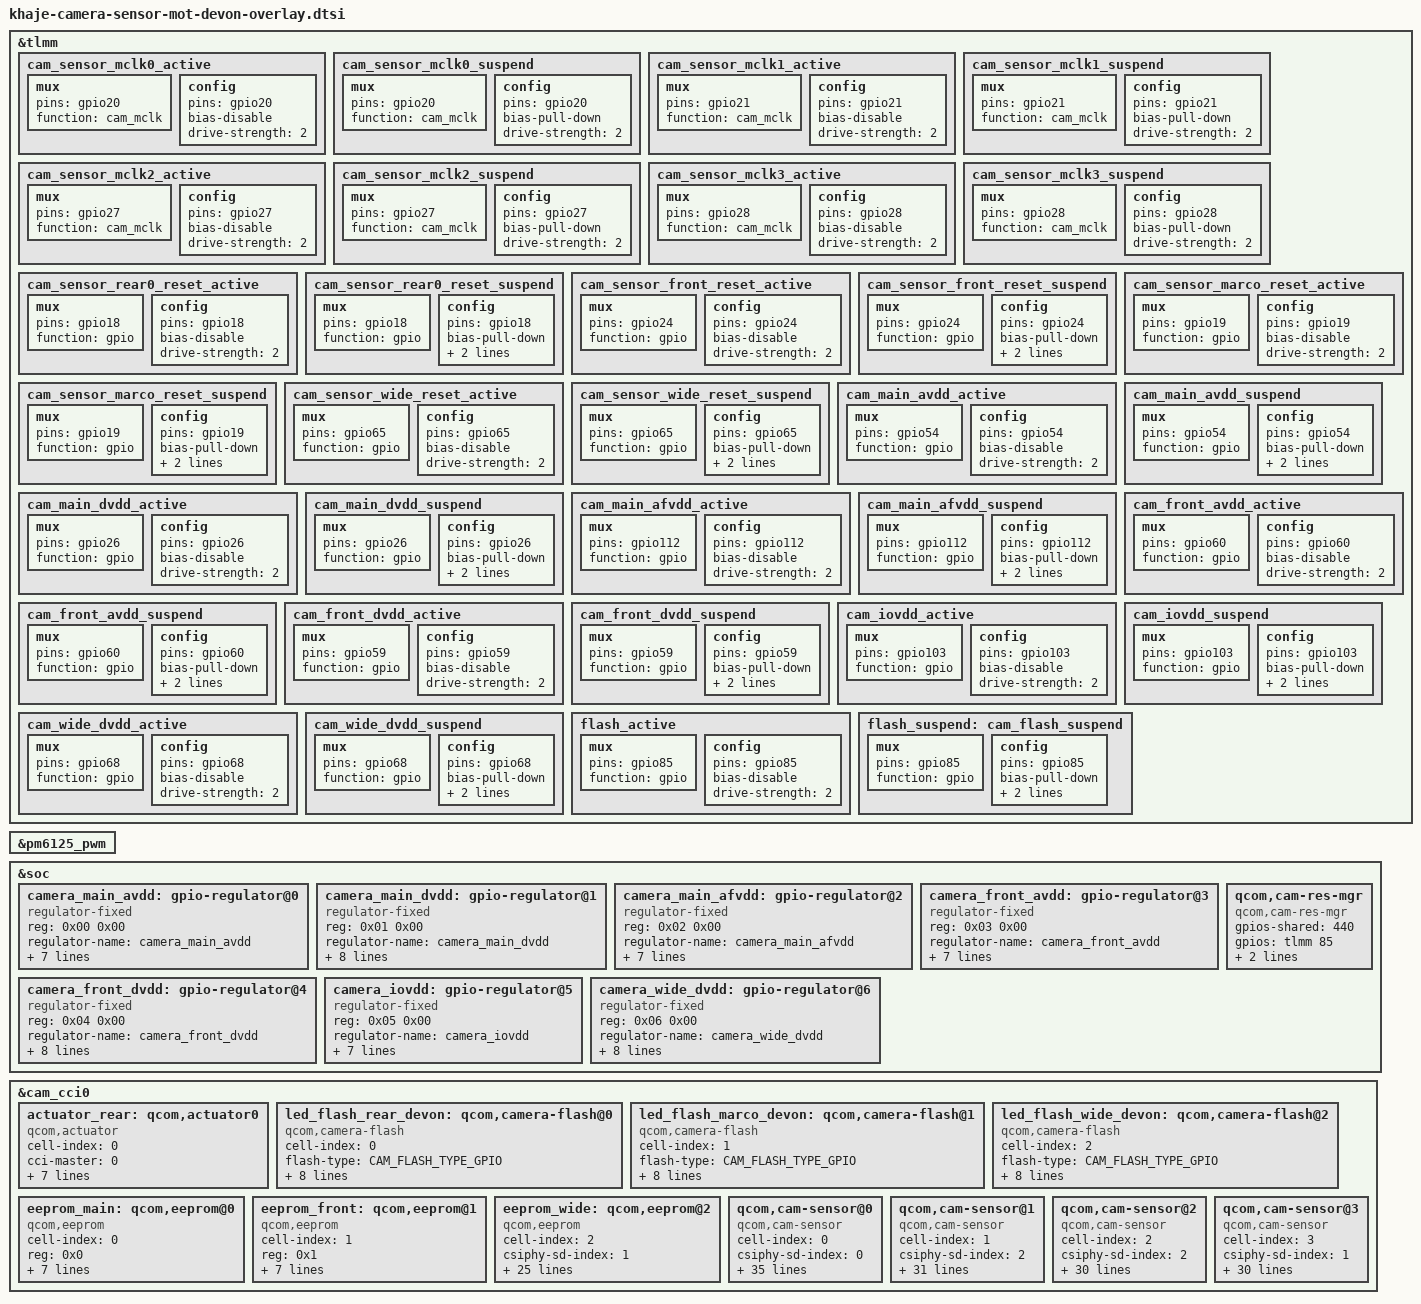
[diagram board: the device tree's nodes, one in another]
#include <dt-bindings/clock/qcom,gcc-khaje.h>
#include <dt-bindings/msm/msm-camera.h>
#include "khaje-camera-flash-pwm.dtsi"

&tlmm {
	cam_sensor_mclk0_active: cam_sensor_mclk0_active {
		/* MCLK 0*/
		mux {
			pins = "gpio20";
			function = "cam_mclk";
		};

		config {
			pins = "gpio20";
			bias-disable;
			drive-strength = <2>;
		};
	};

	cam_sensor_mclk0_suspend: cam_sensor_mclk0_suspend {
		/* MCLK 0*/
		mux {
			pins = "gpio20";
			function = "cam_mclk";
		};

		config {
			pins = "gpio20";
			bias-pull-down;
			drive-strength = <2>;
		};
	};

	cam_sensor_mclk1_active: cam_sensor_mclk1_active {
		mux {
			pins = "gpio21";
			function = "cam_mclk";
		};

		config {
			pins = "gpio21";
			bias-disable; /* No PULL */
			drive-strength = <2>; /* 2 MA */
		};
	};

	cam_sensor_mclk1_suspend: cam_sensor_mclk1_suspend {
		mux {
			pins = "gpio21";
			function = "cam_mclk";
		};

		config {
			pins = "gpio21";
			bias-pull-down;
			drive-strength = <2>; /* 2 MA */
		};
	};

	cam_sensor_mclk2_active: cam_sensor_mclk2_active {
		mux {
			pins = "gpio27";
			function = "cam_mclk";
		};

		config {
			pins = "gpio27";
			bias-disable; /* No PULL */
			drive-strength = <2>; /* 2 MA */
		};
	};

	cam_sensor_mclk2_suspend: cam_sensor_mclk2_suspend {
		mux {
			pins = "gpio27";
			function = "cam_mclk";
		};

		config {
			pins = "gpio27";
			bias-pull-down;
			drive-strength = <2>; /* 2 MA */
		};
	};

	cam_sensor_mclk3_active: cam_sensor_mclk3_active {
		mux {
			pins = "gpio28";
			function = "cam_mclk";
		};

		config {
			pins = "gpio28";
			bias-disable; /* No PULL */
			drive-strength = <2>; /* 2 MA */
		};
	};

	cam_sensor_mclk3_suspend: cam_sensor_mclk3_suspend {
		mux {
			pins = "gpio28";
			function = "cam_mclk";
		};

		config {
			pins = "gpio28";
			bias-pull-down;
			drive-strength = <2>; /* 2 MA */
		};
	};

	cam_sensor_rear0_reset_active: cam_sensor_rear0_reset_active {
		mux {
			pins = "gpio18";
			function = "gpio";
		};

		config {
			pins = "gpio18";
			bias-disable; /* No PULL */
			drive-strength = <2>;
		};
	};

	cam_sensor_rear0_reset_suspend: cam_sensor_rear0_reset_suspend {
		mux {
			pins = "gpio18";
			function = "gpio";
		};

		config {
			pins = "gpio18";
			bias-pull-down; /* PULL DOWN */
			drive-strength = <2>;
			output-low;
		};
	};

	cam_sensor_front_reset_active: cam_sensor_front_reset_active {
		mux {
			pins = "gpio24";
			function = "gpio";
		};

		config {
			pins = "gpio24";
			bias-disable; /* No PULL */
			drive-strength = <2>;
		};
	};

	cam_sensor_front_reset_suspend: cam_sensor_front_reset_suspend {
		mux {
			pins = "gpio24";
			function = "gpio";
		};

		config {
			pins = "gpio24";
			bias-pull-down; /* PULL DOWN */
			drive-strength = <2>;
			output-low;
		};
	};

	cam_sensor_marco_reset_active: cam_sensor_marco_reset_active {
		mux {
			pins = "gpio19";
			function = "gpio";
		};

		config {
			pins = "gpio19";
			bias-disable; /* No PULL */
			drive-strength = <2>;
		};
	};

	cam_sensor_marco_reset_suspend: cam_sensor_marco_reset_suspend {
		mux {
			pins = "gpio19";
			function = "gpio";
		};

		config {
			pins = "gpio19";
			bias-pull-down; /* PULL DOWN */
			drive-strength = <2>;
			output-low;
		};
	};

	cam_sensor_wide_reset_active: cam_sensor_wide_reset_active {
		mux {
			pins = "gpio65";
			function = "gpio";
		};

		config {
			pins = "gpio65";
			bias-disable; /* No PULL */
			drive-strength = <2>;
		};
	};

	cam_sensor_wide_reset_suspend: cam_sensor_wide_reset_suspend {
		mux {
			pins = "gpio65";
			function = "gpio";
		};

		config {
			pins = "gpio65";
			bias-pull-down; /* PULL DOWN */
			drive-strength = <2>;
			output-low;
		};
	};

	cam_main_avdd_active: cam_main_avdd_active {
		/* MAIN AVDD EN */
		mux {
			pins = "gpio54";
			function = "gpio";
		};

		config {
			pins = "gpio54";
			bias-disable; /* No PULL */
			drive-strength = <2>; /* 2 MA */
		};
	};

	cam_main_avdd_suspend: cam_main_avdd_suspend {
		mux {
			pins = "gpio54";
			function = "gpio";
		};

		config {
			pins = "gpio54";
			bias-pull-down; /* PULL DOWN */
			drive-strength = <2>; /* 2 MA */
			output-low;
		};
	};

	cam_main_dvdd_active: cam_main_dvdd_active {
		/* MAIN DVDD EN */
		mux {
			pins = "gpio26";
			function = "gpio";
		};

		config {
			pins = "gpio26";
			bias-disable; /* No PULL */
			drive-strength = <2>; /* 2 MA */
		};
	};

	cam_main_dvdd_suspend: cam_main_dvdd_suspend {
		mux {
			pins = "gpio26";
			function = "gpio";
		};

		config {
			pins = "gpio26";
			bias-pull-down; /* PULL DOWN */
			drive-strength = <2>; /* 2 MA */
			output-low;
		};
	};

	cam_main_afvdd_active: cam_main_afvdd_active {
		/* MAIN AFVDD EN */
		mux {
			pins = "gpio112";
			function = "gpio";
		};

		config {
			pins = "gpio112";
			bias-disable; /* No PULL */
			drive-strength = <2>; /* 2 MA */
		};
	};

	cam_main_afvdd_suspend: cam_main_afvdd_suspend {
		mux {
			pins = "gpio112";
			function = "gpio";
		};

		config {
			pins = "gpio112";
			bias-pull-down; /* PULL DOWN */
			drive-strength = <2>; /* 2 MA */
			output-low;
		};
	};

	cam_front_avdd_active: cam_front_avdd_active {
		/* FRONT AVDD EN */
		mux {
			pins = "gpio60";
			function = "gpio";
		};

		config {
			pins = "gpio60";
			bias-disable; /* No PULL */
			drive-strength = <2>; /* 2 MA */
		};
	};

	cam_front_avdd_suspend: cam_front_avdd_suspend {
		mux {
			pins = "gpio60";
			function = "gpio";
		};

		config {
			pins = "gpio60";
			bias-pull-down; /* PULL DOWN */
			drive-strength = <2>; /* 2 MA */
			output-low;
		};
	};

	cam_front_dvdd_active: cam_front_dvdd_active {
		/* FRONT DVDD EN */
		mux {
			pins = "gpio59";
			function = "gpio";
		};

		config {
			pins = "gpio59";
			bias-disable; /* No PULL */
			drive-strength = <2>; /* 2 MA */
		};
	};

	cam_front_dvdd_suspend: cam_front_dvdd_suspend {
		mux {
			pins = "gpio59";
			function = "gpio";
		};

		config {
			pins = "gpio59";
			bias-pull-down; /* PULL DOWN */
			drive-strength = <2>; /* 2 MA */
			output-low;
		};
	};

	cam_iovdd_active: cam_iovdd_active {
		/* IOVDD EN */
		mux {
			pins = "gpio103";
			function = "gpio";
		};

		config {
			pins = "gpio103";
			bias-disable; /* No PULL */
			drive-strength = <2>; /* 2 MA */
		};
	};

	cam_iovdd_suspend: cam_iovdd_suspend {
		mux {
			pins = "gpio103";
			function = "gpio";
		};

		config {
			pins = "gpio103";
			bias-pull-down; /* PULL DOWN */
			drive-strength = <2>; /* 2 MA */
			output-low;
		};
	};

	cam_wide_dvdd_active: cam_wide_dvdd_active {
		/* WIDE DVDD EN */
		mux {
			pins = "gpio68";
			function = "gpio";
		};

		config {
			pins = "gpio68";
			bias-disable; /* No PULL */
			drive-strength = <2>; /* 2 MA */
		};
	};

	cam_wide_dvdd_suspend: cam_wide_dvdd_suspend {
		mux {
			pins = "gpio68";
			function = "gpio";
		};

		config {
			pins = "gpio68";
			bias-pull-down; /* PULL DOWN */
			drive-strength = <2>; /* 2 MA */
			output-low;
		};
	};

	flash_active: flash_active {
		/* FLASH */
		mux {
			pins = "gpio85";
			function = "gpio";
		};

		config {
			pins = "gpio85";
			bias-disable; /* No PULL */
			drive-strength = <2>; /* 2 MA */
		};
	};

	flash_suspend: cam_flash_suspend {
		/* FLASH */
		mux {
			pins = "gpio85";
			function = "gpio";
		};

		config {
			pins = "gpio85";
			bias-pull-down; /* PULL DOWN */
			drive-strength = <2>; /* 2 MA */
			output-low;
		};
	};

};

&pm6125_pwm {
	status = "ok";
};

&soc {

	camera_main_avdd: gpio-regulator@0 {
		compatible = "regulator-fixed";
		reg = <0x00 0x00>;
		regulator-name = "camera_main_avdd";
		regulator-min-microvolt = <2800000>;
		regulator-max-microvolt = <2800000>;
		regulator-enable-ramp-delay = <233>;
		enable-active-high;
		gpio = <&tlmm 54 0>;
		pinctrl-names = "default";
		pinctrl-0 = <&cam_main_avdd_active>;
		pinctrl-1 = <&cam_main_avdd_suspend>;
		//vin-supply = <&VPH_PWR>;
	};

	camera_main_dvdd: gpio-regulator@1 {
		compatible = "regulator-fixed";
		reg = <0x01 0x00>;
		regulator-name = "camera_main_dvdd";
		regulator-min-microvolt = <1050000>;
		regulator-max-microvolt = <1050000>;
		regulator-enable-ramp-delay = <233>;
		enable-active-high;
		gpio = <&tlmm 26 0>;
		pinctrl-names = "default";
		pinctrl-0 = <&cam_main_dvdd_active>;
		pinctrl-1 = <&cam_main_dvdd_suspend>;
		vin-supply = <&S7A>;
	};

	camera_main_afvdd: gpio-regulator@2 {
		compatible = "regulator-fixed";
		reg = <0x02 0x00>;
		regulator-name = "camera_main_afvdd";
		regulator-min-microvolt = <2800000>;
		regulator-max-microvolt = <2800000>;
		regulator-enable-ramp-delay = <233>;
		enable-active-high;
		gpio = <&tlmm 112 0>;
		pinctrl-names = "default";
		pinctrl-0 = <&cam_main_afvdd_active>;
		pinctrl-1 = <&cam_main_afvdd_suspend>;
		//vin-supply = <&VPH_PWR>;
	};

	camera_front_avdd: gpio-regulator@3 {
		compatible = "regulator-fixed";
		reg = <0x03 0x00>;
		regulator-name = "camera_front_avdd";
		regulator-min-microvolt = <2800000>;
		regulator-max-microvolt = <2800000>;
		regulator-enable-ramp-delay = <233>;
		enable-active-high;
		gpio = <&tlmm 60 0>;
		pinctrl-names = "default";
		pinctrl-0 = <&cam_front_avdd_active>;
		pinctrl-1 = <&cam_front_avdd_suspend>;
		//vin-supply = <&VPH_PWR>;
	};

	camera_front_dvdd: gpio-regulator@4 {
		compatible = "regulator-fixed";
		reg = <0x04 0x00>;
		regulator-name = "camera_front_dvdd";
		regulator-min-microvolt = <1200000>;
		regulator-max-microvolt = <1200000>;
		regulator-enable-ramp-delay = <233>;
		enable-active-high;
		gpio = <&tlmm 59 0>;
		pinctrl-names = "default";
		pinctrl-0 = <&cam_front_dvdd_active>;
		pinctrl-1 = <&cam_front_dvdd_suspend>;
		vin-supply = <&S7A>;
	};

	camera_iovdd: gpio-regulator@5 {
		compatible = "regulator-fixed";
		reg = <0x05 0x00>;
		regulator-name = "camera_iovdd";
		regulator-min-microvolt = <1800000>;
		regulator-max-microvolt = <1800000>;
		regulator-enable-ramp-delay = <233>;
		enable-active-high;
		gpio = <&tlmm 103 0>;
		pinctrl-names = "default";
		pinctrl-0 = <&cam_iovdd_active>;
		pinctrl-1 = <&cam_iovdd_suspend>;
		//vin-supply = <&VPH_PWR>;
	};

	camera_wide_dvdd: gpio-regulator@6 {
		compatible = "regulator-fixed";
		reg = <0x06 0x00>;
		regulator-name = "camera_wide_dvdd";
		regulator-min-microvolt = <1200000>;
		regulator-max-microvolt = <1200000>;
		regulator-enable-ramp-delay = <233>;
		enable-active-high;
		gpio = <&tlmm 68 0>;
		pinctrl-names = "default";
		pinctrl-0 = <&cam_wide_dvdd_active>;
		pinctrl-1 = <&cam_wide_dvdd_suspend>;
		vin-supply = <&S7A>;
	};

	qcom,cam-res-mgr {
		compatible = "qcom,cam-res-mgr";
		status = "ok";
		gpios-shared = <440>;
		gpios = <&tlmm 85 0>;
		pinctrl-names = "flash_active", "flash_suspend";
		pinctrl-0 = <&flash_active>;
		pinctrl-1 = <&flash_suspend>;
	};
};

&cam_cci0 {
	actuator_rear: qcom,actuator0 {
		cell-index = <0>;
		compatible = "qcom,actuator";
		cci-master = <0>;
		cam_vaf-supply = <&camera_main_afvdd>;
		regulator-names = "cam_vaf";
		rgltr-cntrl-support;
		rgltr-min-voltage = <2800000>;
		rgltr-max-voltage = <2800000>;
		rgltr-load-current = <2800000>;
		status = "ok";
		multi-user-support;
	};

	led_flash_rear_devon: qcom,camera-flash@0 {
		cell-index = <0>;
		compatible = "qcom,camera-flash";
		flash-type = <CAM_FLASH_TYPE_GPIO>;
		gpio-no-mux = <0>;
		pinctrl-names = "cam_default", "cam_suspend";
		pinctrl-0 = <&flash_active>;
		pinctrl-1 = <&flash_suspend>;
		gpios = <&tlmm 85 0>;
		gpio-custom1 = <0>;
		gpio-req-tbl-num = <0>;
		gpio-req-tbl-flags = <0>;
		gpio-req-tbl-label = "CUSTOM_GPIO1";
		status = "ok";
	};

	led_flash_marco_devon: qcom,camera-flash@1 {
		cell-index = <1>;
		compatible = "qcom,camera-flash";
		flash-type = <CAM_FLASH_TYPE_GPIO>;
		gpio-no-mux = <0>;
		pinctrl-names = "cam_default", "cam_suspend";
		pinctrl-0 = <&flash_active>;
		pinctrl-1 = <&flash_suspend>;
		gpios = <&tlmm 85 0>;
		gpio-custom1 = <0>;
		gpio-req-tbl-num = <0>;
		gpio-req-tbl-flags = <0>;
		gpio-req-tbl-label = "CUSTOM_GPIO1";
		status = "ok";
	};

	led_flash_wide_devon: qcom,camera-flash@2 {
		cell-index = <2>;
		compatible = "qcom,camera-flash";
		flash-type = <CAM_FLASH_TYPE_GPIO>;
		gpio-no-mux = <0>;
		pinctrl-names = "cam_default", "cam_suspend";
		pinctrl-0 = <&flash_active>;
		pinctrl-1 = <&flash_suspend>;
		gpios = <&tlmm 85 0>;
		gpio-custom1 = <0>;
		gpio-req-tbl-num = <0>;
		gpio-req-tbl-flags = <0>;
		gpio-req-tbl-label = "CUSTOM_GPIO1";
		status = "ok";
	};

	eeprom_main: qcom,eeprom@0 {
		cell-index = <0>;
		reg = <0x0>;
		compatible = "qcom,eeprom";
		cam_vio-supply = <&camera_iovdd>;
		regulator-names = "cam_vio";
		rgltr-cntrl-support;
		rgltr-min-voltage = <1800000>;
		rgltr-max-voltage = <1800000>;
		rgltr-load-current = <120000>;
		cci-master = <0>;
		status = "ok";
	};

	eeprom_front: qcom,eeprom@1 {
		cell-index = <1>;
		reg = <0x1>;
		compatible = "qcom,eeprom";
		cam_vio-supply = <&camera_iovdd>;
		regulator-names = "cam_vio";
		rgltr-cntrl-support;
		rgltr-min-voltage = <1800000>;
		rgltr-max-voltage = <1800000>;
		rgltr-load-current = <120000>;
		cci-master = <1>;
		status = "ok";
	};

	eeprom_wide:qcom,eeprom@2 {
		cell-index = <2>;
		compatible = "qcom,eeprom";
		csiphy-sd-index = <1>;
		cam_vio-supply = <&camera_iovdd>;
		cam_vdig-supply = <&camera_wide_dvdd>;
		cam_clk-supply = <&gcc_camss_top_gdsc>;
		regulator-names = "cam_vio", "cam_vdig",
			"cam_clk";
		rgltr-cntrl-support;
		pwm-switch;
		rgltr-min-voltage = <1800000 1200000 0>;
		rgltr-max-voltage = <1800000 1200000 0>;
		rgltr-load-current = <120000 1200000 0>;
		gpio-no-mux = <0>;
		pinctrl-names = "cam_default", "cam_suspend";
		pinctrl-0 = <&cam_sensor_mclk2_active
					&cam_sensor_wide_reset_active>;
		pinctrl-1 = <&cam_sensor_mclk2_suspend
					&cam_sensor_wide_reset_suspend>;
		gpios = <&tlmm 27 0>,
				<&tlmm 65 0>,
				<&pm6125_gpios 2 0>;
		gpio-reset = <1>;
		gpio-custom1 = <2>;
		gpio-req-tbl-num = <0 1 2>;
		gpio-req-tbl-flags = <1 0 0>;
		gpio-req-tbl-label = "CAMIF_MCLK2",
					"CAM_RESET2",
					"CAM_VANA2";
		cci-master = <1>;
		status = "ok";
		clocks = <&gcc GCC_CAMSS_MCLK2_CLK>;
		clock-names = "cam_clk";
		clock-cntl-level = "turbo";
		clock-rates = <24000000>;
	};

	 /* main : JN1*/
	qcom,cam-sensor@0 {
		cell-index = <0>;
		compatible = "qcom,cam-sensor";
		csiphy-sd-index = <0>;
		sensor-position-roll = <90>;
		sensor-position-pitch = <0>;
		sensor-position-yaw = <180>;
		led-flash-src = <&led_flash_rear_devon>;
		eeprom-src = <&eeprom_main>;
		actuator-src = <&actuator_rear>;
		cam_vaf-supply = <&camera_main_afvdd>;
		cam_vio-supply = <&camera_iovdd>;
		cam_vana-supply = <&camera_main_avdd>;
		cam_vdig-supply = <&camera_main_dvdd>;
		cam_clk-supply = <&gcc_camss_top_gdsc>;
		regulator-names ="cam_vio", "cam_vana", "cam_vdig",
			"cam_clk", "cam_vaf";
		rgltr-cntrl-support;
		pwm-switch;
		rgltr-min-voltage = <1800000 2800000 1050000 0 2800000>;
		rgltr-max-voltage = <1800000 2800000 1050000 0 2800000>;
		rgltr-load-current = <120000 80000 1200000 0 100000>;
		gpio-no-mux = <0>;
		pinctrl-names = "cam_default", "cam_suspend";
		pinctrl-0 = <&cam_sensor_mclk0_active
				&cam_sensor_rear0_reset_active>;
		pinctrl-1 = <&cam_sensor_mclk0_suspend
				&cam_sensor_rear0_reset_suspend>;
		gpios = <&tlmm 20 0>,
			<&tlmm 18 0>;
		gpio-reset = <1>;
		gpio-req-tbl-num = <0 1>;
		gpio-req-tbl-flags = <1 0>;
		gpio-req-tbl-label = "CAMIF_MCLK0",
					"CAM_RESET0";
		cci-master = <0>;
		status = "ok";
		clocks = <&gcc GCC_CAMSS_MCLK0_CLK>;
		clock-names = "cam_clk";
		clock-cntl-level = "turbo";
		clock-rates = <24000000>;
	};

	/*front*/
	 qcom,cam-sensor@1 {
		cell-index = <1>;
		compatible = "qcom,cam-sensor";
		csiphy-sd-index = <2>;
		sensor-position-roll = <270>;
		sensor-position-pitch = <0>;
		sensor-position-yaw = <180>;
		eeprom-src = <&eeprom_front>;
		cam_vio-supply = <&camera_iovdd>;
		cam_vana-supply = <&camera_front_avdd>;
		cam_vdig-supply = <&camera_front_dvdd>;
		cam_clk-supply = <&gcc_camss_top_gdsc>;
		regulator-names = "cam_vio", "cam_vana", "cam_vdig",
			"cam_clk";
		rgltr-cntrl-support;
		pwm-switch;
		rgltr-min-voltage = <1800000 2800000 1200000 0>;
		rgltr-max-voltage = <1800000 2800000 1200000 0>;
		rgltr-load-current = <120000 80000 1200000 0>;
		gpio-no-mux = <0>;
		pinctrl-names = "cam_default", "cam_suspend";
		pinctrl-0 = <&cam_sensor_mclk1_active
					&cam_sensor_front_reset_active>;
		pinctrl-1 = <&cam_sensor_mclk1_suspend
					&cam_sensor_front_reset_suspend>;
		gpios = <&tlmm 21 0>,
				<&tlmm 24 0>,
				<&pm6125_gpios 1 0>;
		gpio-reset = <1>;
		gpio-custom1 = <2>;
		gpio-req-tbl-num = <0 1 2>;
		gpio-req-tbl-flags = <1 0 0>;
		gpio-req-tbl-label = "CAMIF_MCLK1",
					"CAM_RESET1",
					"CAM_MIPI_SEL";
		cci-master = <1>;
		status = "ok";
		clocks = <&gcc GCC_CAMSS_MCLK1_CLK>;
		clock-names = "cam_clk";
		clock-cntl-level = "turbo";
		clock-rates = <24000000>;
	};

	/*marco*/
	 qcom,cam-sensor@2 {
		cell-index = <2>;
		compatible = "qcom,cam-sensor";
		csiphy-sd-index = <2>;
		sensor-position-roll = <270>;
		sensor-position-pitch = <0>;
		sensor-position-yaw = <180>;
		led-flash-src = <&led_flash_marco_devon>;
		cam_vio-supply = <&camera_iovdd>;
		cam_clk-supply = <&gcc_camss_top_gdsc>;
		regulator-names = "cam_vio", "cam_clk";
		rgltr-cntrl-support;
		pwm-switch;
		rgltr-min-voltage = <1800000 0>;
		rgltr-max-voltage = <1800000 0>;
		rgltr-load-current = <120000 0>;
		gpio-no-mux = <0>;
		pinctrl-names = "cam_default", "cam_suspend";
		pinctrl-0 = <&cam_sensor_mclk3_active
					&cam_sensor_marco_reset_active>;
		pinctrl-1 = <&cam_sensor_mclk3_suspend
					&cam_sensor_marco_reset_suspend>;
		gpios = <&tlmm 28 0>,
				<&tlmm 19 0>,
				<&pm6125_gpios 9 0>,
				<&pm6125_gpios 1 0>;
		gpio-reset = <1>;
		gpio-custom1 = <2>;
		gpio-custom2 = <3>;
		gpio-req-tbl-num = <0 1 2 3>;
		gpio-req-tbl-flags = <1 0 0 0>;
		gpio-req-tbl-label = "CAMIF_MCLK3",
					"CAM_RESET3",
					"CAM_VANA3",
					"CAM_MIPI_SEL";
		cci-master = <0>;
		status = "ok";
		clocks = <&gcc GCC_CAMSS_MCLK3_CLK>;
		clock-names = "cam_clk";
		clock-cntl-level = "turbo";
		clock-rates = <24000000>;
	};

	/*Wide*/
	 qcom,cam-sensor@3 {
		cell-index = <3>;
		compatible = "qcom,cam-sensor";
		csiphy-sd-index = <1>;
		sensor-position-roll = <270>;
		sensor-position-pitch = <0>;
		sensor-position-yaw = <180>;
		led-flash-src = <&led_flash_wide_devon>;
		eeprom-src = <&eeprom_wide>;
		cam_vio-supply = <&camera_iovdd>;
		cam_vdig-supply = <&camera_wide_dvdd>;
		cam_clk-supply = <&gcc_camss_top_gdsc>;
		regulator-names = "cam_vio", "cam_vdig",
			"cam_clk";
		rgltr-cntrl-support;
		pwm-switch;
		rgltr-min-voltage = <1800000 1200000 0>;
		rgltr-max-voltage = <1800000 1200000 0>;
		rgltr-load-current = <120000 1200000 0>;
		gpio-no-mux = <0>;
		pinctrl-names = "cam_default", "cam_suspend";
		pinctrl-0 = <&cam_sensor_mclk2_active
					&cam_sensor_wide_reset_active>;
		pinctrl-1 = <&cam_sensor_mclk2_suspend
					&cam_sensor_wide_reset_suspend>;
		gpios = <&tlmm 27 0>,
				<&tlmm 65 0>,
				<&pm6125_gpios 2 0>;
		gpio-reset = <1>;
		gpio-custom1 = <2>;
		gpio-req-tbl-num = <0 1 2>;
		gpio-req-tbl-flags = <1 0 0>;
		gpio-req-tbl-label = "CAMIF_MCLK2",
					"CAM_RESET2",
					"CAM_VANA2";
		cci-master = <1>;
		status = "ok";
		clocks = <&gcc GCC_CAMSS_MCLK2_CLK>;
		clock-names = "cam_clk";
		clock-cntl-level = "turbo";
		clock-rates = <24000000>;
	};
};
